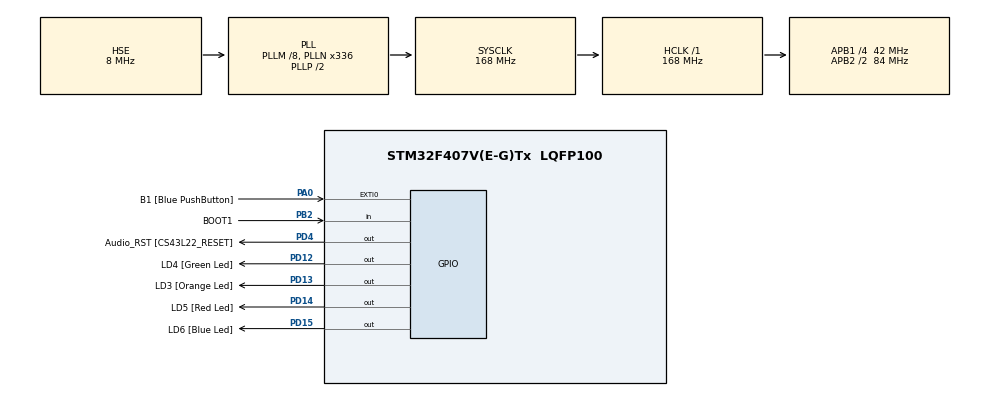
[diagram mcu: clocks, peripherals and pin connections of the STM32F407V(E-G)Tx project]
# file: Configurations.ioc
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FREERTOS.Tasks01=Task1,9,128,R_Task1,Default,NULL,Dynamic,NULL,NULL;Task2,9,128,R_Task2,Default,NULL,Dynamic,NULL,NULL
Mcu.Family=STM32F4
Mcu.Name=STM32F407V(E-G)Tx
Mcu.Package=LQFP100
NVIC.PriorityGroup=NVIC_PRIORITYGROUP_4
NVIC.TIM7_IRQn=true\:0\:0\:false\:false\:true\:false\:false\:true
NVIC.TimeBase=TIM7_IRQn
NVIC.TimeBaseIP=TIM7
PA0-WKUP.GPIO_Label=B1 [Blue PushButton]
PA0-WKUP.GPIO_ModeDefaultEXTI=GPIO_MODE_EVT_RISING
PA0-WKUP.GPIO_PuPd=GPIO_NOPULL
PA0-WKUP.Signal=GPXTI0
PB10.GPIO_Label=CLK_IN [MP45DT02_CLK]
PB10.GPIO_Mode=GPIO_MODE_AF_PP
PB10.GPIO_PuPd=GPIO_NOPULL
PB10.GPIO_Speed=GPIO_SPEED_FREQ_LOW
PB10.Signal=I2S2_CK
PB2.GPIO_Label=BOOT1
PB2.GPIO_Mode=GPIO_MODE_INPUT
PB2.GPIO_PuPd=GPIO_NOPULL
PB2.Signal=GPIO_Input
PD12.GPIO_Label=LD4 [Green Led]
PD12.GPIO_PuPd=GPIO_NOPULL
PD12.GPIO_Speed=GPIO_SPEED_FREQ_LOW
PD12.Signal=GPIO_Output
PD13.GPIO_Label=LD3 [Orange Led]
PD13.GPIO_PuPd=GPIO_NOPULL
PD13.GPIO_Speed=GPIO_SPEED_FREQ_LOW
PD13.Signal=GPIO_Output
PD14.GPIO_Label=LD5 [Red Led]
PD14.GPIO_PuPd=GPIO_NOPULL
PD14.GPIO_Speed=GPIO_SPEED_FREQ_LOW
PD14.Signal=GPIO_Output
PD15.GPIO_Label=LD6 [Blue Led]
PD15.GPIO_PuPd=GPIO_NOPULL
PD15.GPIO_Speed=GPIO_SPEED_FREQ_LOW
PD15.Signal=GPIO_Output
PD4.GPIO_Label=Audio_RST [CS43L22_RESET]
PD4.GPIO_PuPd=GPIO_NOPULL
PD4.GPIO_Speed=GPIO_SPEED_FREQ_LOW
PD4.Signal=GPIO_Output
PH0-OSC_IN.GPIO_Label=PH0-OSC_IN
PH0-OSC_IN.Mode=HSE-External-Oscillator
PH0-OSC_IN.Signal=RCC_OSC_IN
PH1-OSC_OUT.GPIO_Label=PH1-OSC_OUT
PH1-OSC_OUT.Mode=HSE-External-Oscillator
PH1-OSC_OUT.Signal=RCC_OSC_OUT
ProjectManager.HeapSize=0x200
ProjectManager.StackSize=0x400
ProjectManager.TargetToolchain=TrueSTUDIO
RCC.48MHZClocksFreq_Value=48000000
RCC.AHBFreq_Value=168000000
RCC.APB1CLKDivider=RCC_HCLK_DIV4
RCC.APB1Freq_Value=42000000
RCC.APB1TimFreq_Value=84000000
RCC.APB2CLKDivider=RCC_HCLK_DIV2
RCC.APB2Freq_Value=84000000
RCC.APB2TimFreq_Value=168000000
RCC.CortexFreq_Value=168000000
RCC.HCLKFreq_Value=168000000
RCC.HSE_VALUE=8000000
RCC.HSI_VALUE=16000000
RCC.LSE_VALUE=32768
RCC.PLLM=8
RCC.PLLN=336
RCC.PLLQ=7
RCC.PLLSourceVirtual=RCC_PLLSOURCE_HSE
RCC.SYSCLKFreq_VALUE=168000000
RCC.SYSCLKSource=RCC_SYSCLKSOURCE_PLLCLK
RCC.VCOOutputFreq_Value=336000000
VP_FREERTOS_VS_CMSIS_V2.Mode=CMSIS_V2
VP_SYS_VS_tim7.Mode=TIM7
board=STM32F4DISCOVERY

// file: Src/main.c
/* USER CODE BEGIN Header */
/**
  ******************************************************************************
  * @file           : main.c
  * @brief          : Main program body
  ******************************************************************************
  * @attention
  *
  * <h2><center>&copy; Copyright (c) 2020 STMicroelectronics.
  * All rights reserved.</center></h2>
  *
  * This software component is licensed by ST under Ultimate Liberty license
  * SLA0044, the "License"; You may not use this file except in compliance with
  * the License. You may obtain a copy of the License at:
  *                             www.st.com/SLA0044
  *
  ******************************************************************************
  */
/* USER CODE END Header */

#include "main.h"
#include "cmsis_os.h"

osThreadId_t Task1Handle;
osThreadId_t Task2Handle;

void SystemClock_Config(void);
static void MX_GPIO_Init(void);
void R_Task1(void *argument); // for v2
void R_Task2(void *argument); // for v2

int main(void)
{

  /* MCU Configuration--------------------------------------------------------*/

  /* Reset of all peripherals, Initializes the Flash interface and the Systick. */
  HAL_Init();

  /* Configure the system clock */
  SystemClock_Config();

  /* Initialize all configured peripherals */
  MX_GPIO_Init();

  osKernelInitialize(); // Initialize CMSIS-RTOS

  /* Create the thread(s) */
  /* definition and creation of Task1 */
  const osThreadAttr_t Task1_attributes = {
    .name = "Task1",
    .priority = (osPriority_t) osPriorityLow1,
    .stack_size = 128
  };
  Task1Handle = osThreadNew(R_Task1, NULL, &Task1_attributes);

  /* definition and creation of Task2 */
  const osThreadAttr_t Task2_attributes = {
    .name = "Task2",
    .priority = (osPriority_t) osPriorityLow1,
    .stack_size = 128
  };
  Task2Handle = osThreadNew(R_Task2, NULL, &Task2_attributes);

  /* Start scheduler */
  osKernelStart();

  /* We should never get here as control is now taken by the scheduler */

  /* Infinite loop */
  while (1)
  {

  }
}

void SystemClock_Config(void)
{
  RCC_OscInitTypeDef RCC_OscInitStruct = {0};
  RCC_ClkInitTypeDef RCC_ClkInitStruct = {0};

  /** Configure the main internal regulator output voltage
  */
  __HAL_RCC_PWR_CLK_ENABLE();
  __HAL_PWR_VOLTAGESCALING_CONFIG(PWR_REGULATOR_VOLTAGE_SCALE1);
  /** Initializes the CPU, AHB and APB busses clocks
  */
  RCC_OscInitStruct.OscillatorType = RCC_OSCILLATORTYPE_HSE;
  RCC_OscInitStruct.HSEState = RCC_HSE_ON;
  RCC_OscInitStruct.PLL.PLLState = RCC_PLL_ON;
  RCC_OscInitStruct.PLL.PLLSource = RCC_PLLSOURCE_HSE;
  RCC_OscInitStruct.PLL.PLLM = 8;
  RCC_OscInitStruct.PLL.PLLN = 336;
  RCC_OscInitStruct.PLL.PLLP = RCC_PLLP_DIV2;
  RCC_OscInitStruct.PLL.PLLQ = 7;
  if (HAL_RCC_OscConfig(&RCC_OscInitStruct) != HAL_OK)
  {
    Error_Handler();
  }
  /** Initializes the CPU, AHB and APB busses clocks
  */
  RCC_ClkInitStruct.ClockType = RCC_CLOCKTYPE_HCLK|RCC_CLOCKTYPE_SYSCLK
                              |RCC_CLOCKTYPE_PCLK1|RCC_CLOCKTYPE_PCLK2;
  RCC_ClkInitStruct.SYSCLKSource = RCC_SYSCLKSOURCE_PLLCLK;
  RCC_ClkInitStruct.AHBCLKDivider = RCC_SYSCLK_DIV1;
  RCC_ClkInitStruct.APB1CLKDivider = RCC_HCLK_DIV4;
  RCC_ClkInitStruct.APB2CLKDivider = RCC_HCLK_DIV2;

  if (HAL_RCC_ClockConfig(&RCC_ClkInitStruct, FLASH_LATENCY_5) != HAL_OK)
  {
    Error_Handler();
  }
}

static void MX_GPIO_Init(void)
{
  GPIO_InitTypeDef GPIO_InitStruct = {0};

  /* GPIO Ports Clock Enable */
  __HAL_RCC_GPIOH_CLK_ENABLE();
  __HAL_RCC_GPIOA_CLK_ENABLE();
  __HAL_RCC_GPIOB_CLK_ENABLE();
  __HAL_RCC_GPIOD_CLK_ENABLE();

  /*Configure GPIO pin Output Level */
  HAL_GPIO_WritePin(GPIOD, LD4_Pin|LD3_Pin|LD5_Pin|LD6_Pin
                          |Audio_RST_Pin, GPIO_PIN_RESET);

  /*Configure GPIO pin : B1_Pin */
  GPIO_InitStruct.Pin = B1_Pin;
  GPIO_InitStruct.Mode = GPIO_MODE_EVT_RISING;
  GPIO_InitStruct.Pull = GPIO_NOPULL;
  HAL_GPIO_Init(B1_GPIO_Port, &GPIO_InitStruct);

  /*Configure GPIO pin : BOOT1_Pin */
  GPIO_InitStruct.Pin = BOOT1_Pin;
  GPIO_InitStruct.Mode = GPIO_MODE_INPUT;
  GPIO_InitStruct.Pull = GPIO_NOPULL;
  HAL_GPIO_Init(BOOT1_GPIO_Port, &GPIO_InitStruct);

  /*Configure GPIO pin : CLK_IN_Pin */
  GPIO_InitStruct.Pin = CLK_IN_Pin;
  GPIO_InitStruct.Mode = GPIO_MODE_AF_PP;
  GPIO_InitStruct.Pull = GPIO_NOPULL;
  GPIO_InitStruct.Speed = GPIO_SPEED_FREQ_LOW;
  GPIO_InitStruct.Alternate = GPIO_AF5_SPI2;
  HAL_GPIO_Init(CLK_IN_GPIO_Port, &GPIO_InitStruct);

  /*Configure GPIO pins : LD4_Pin LD3_Pin LD5_Pin LD6_Pin
                           Audio_RST_Pin */
  GPIO_InitStruct.Pin = LD4_Pin|LD3_Pin|LD5_Pin|LD6_Pin
                          |Audio_RST_Pin;
  GPIO_InitStruct.Mode = GPIO_MODE_OUTPUT_PP;
  GPIO_InitStruct.Pull = GPIO_NOPULL;
  GPIO_InitStruct.Speed = GPIO_SPEED_FREQ_LOW;
  HAL_GPIO_Init(GPIOD, &GPIO_InitStruct);

}

void R_Task1(void *argument)
{

  /* USER CODE BEGIN 5 */
  const TickType_t xR_Task1_Time = pdMS_TO_TICKS(500);
  /* Infinite loop */
  for(;;)
  {
	HAL_GPIO_TogglePin(GPIOD, GPIO_PIN_12);
    osDelay(xR_Task1_Time);
  }
  /* USER CODE END 5 */
}

void R_Task2(void *argument)
{
  /* USER CODE BEGIN R_Task2 */
  const TickType_t xR_Task2_Time = pdMS_TO_TICKS(500);
  /* Infinite loop */
  for(;;)
  {
	  HAL_GPIO_TogglePin(GPIOD, GPIO_PIN_13);
	  osDelay(xR_Task2_Time);
  }
  /* USER CODE END R_Task2 */
}

void HAL_TIM_PeriodElapsedCallback(TIM_HandleTypeDef *htim)
{
  if (htim->Instance == TIM7) {
    HAL_IncTick();
  }
}

void Error_Handler(void)
{
}

/************************ (C) COPYRIGHT STMicroelectronics *****END OF FILE****/
